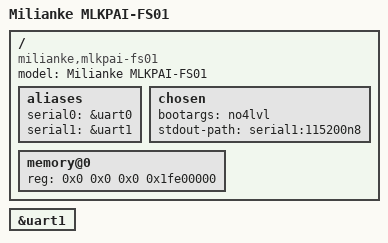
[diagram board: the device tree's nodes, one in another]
// SPDX-License-Identifier: GPL-2.0 OR MIT
/*
 * Copyright (C) 2025 Junhui Liu <junhui.liu@pigmoral.tech>
 */

#include "dr1v90.dtsi"

/ {
	model = "Milianke MLKPAI-FS01";
	compatible = "milianke,mlkpai-fs01", "anlogic,dr1v90";

	aliases {
		serial0 = &uart0;
		serial1 = &uart1;
	};

	chosen {
		bootargs = "no4lvl"; /* DR1V90 hangs on SV48 */
		stdout-path = "serial1:115200n8";
	};

	memory@0 {
		device_type = "memory";
		reg = <0x0 0x0 0x0 0x1fe00000>;
	};
};

&uart1 {
	status = "okay";
};
